# TMS320F280049 register map
Vendor: Texas Instruments; Series: C2000 F28004x; File version: 0.2.0-generated
Registers are 16-bit, read-write, reset 0x0 unless marked. A register's access mark holds for its fields unless they carry their own. Offsets are from the block's base; [hi:lo] are bit positions; {n}, {i} and the like mark numbered series.

## CLA2NOTVISIBLE
Base 0x00002800
0x2C MPISRCSEL2 32-bit — Peripheral Interrupt Source Select Register 2
0x4E MIPCTL — Interrupt Prioriry Register
0x80 MDEBUGCTL — Legacy CLA Debug Control Register
0x82 MDEBUGSS — Legacy CLA Debug Single Step Register
0x84 MPSACTL — CLA PSA Control Register
0x88 MPSA1 32-bit — CLA PSA Register 1
0x8C MPSA2 32-bit — CLA PSA Register 2
0xA0 MHWADBGCAP 32-bit — TI HWA Debug Capabilities
0xA4 MHWADBGCTL 32-bit — TI HWA Debug Control

## ECAP1REGS — ECAP Registers
Base 0x0000A400
Same registers: ECAP2REGS 0x0000A480, ECAP3REGS 0x0000A500, ECAP4REGS 0x0000A580, ECAP5REGS 0x0000A600, ECAP6REGS 0x0000A680, ECAP7REGS 0x0000A700
0x00 TSCTR 32-bit — Time-Stamp Counter
  [31] TSCTR — Time Stamp Counter
0x04 CTRPHS 32-bit — Counter Phase Offset Value Register
  [31] CTRPHS — Counter phase
{0x4+4i} CAP{i} 32-bit (i=1..4) — Capture {i} Register
  [31] CAP{i} — Capture {i}
0x24 ECCTL0 32-bit — Capture Control Register 0
  [12:6] INPUTSEL — INPUT source select
0x28 ECCTL1 — Capture Control Register 1
  [15] FREE_SOFT — Emulation mode
  [15:13] PRESCALE — Event Filter prescale select
  [8] CAPLDEN — Enable Loading CAP1-4 regs on a Cap Event
  [2n-1] CTRRST{n} (n=1..4) — Counter Reset on Capture Event {n}
  [2n-2] CAP{n}POL (n=1..4) — Capture Event {n} Polarity select
0x2A ECCTL2 — Capture Control Register 2
  [15] MODCNTRSTS — modulo counter status
  [14:13] DMAEVTSEL — DMA event select
  [11] CTRFILTRESET — Reset event filter, modulus counter, and interrupt flags.
  [10] APWMPOL — APWM output polarity select
  [9] CAP_APWM — CAP/APWM operating mode select
  [8] SWSYNC — SW forced counter sync
  [8:7] SYNCO_SEL — Sync-out mode
  [5] SYNCI_EN — Counter sync-in select
  [4] TSCTRSTOP — TSCNT counter stop
  [3] REARM — One-shot re-arm
  [3:2] STOP_WRAP — Stop value for one-shot, Wrap for continuous
  [0] CONT_ONESHT — Continuous or one-shot
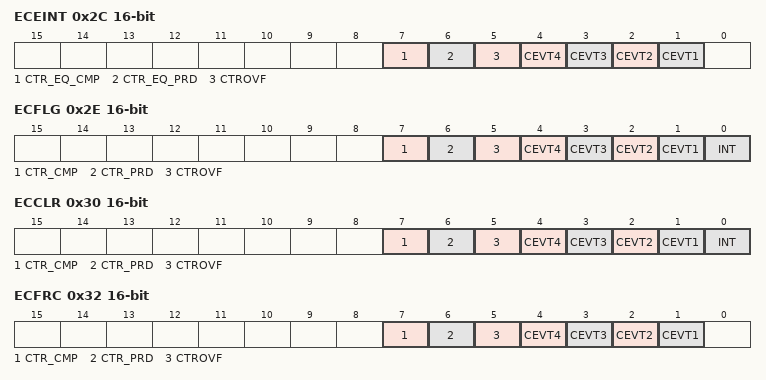
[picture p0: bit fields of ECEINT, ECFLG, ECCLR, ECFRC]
0x2C ECEINT — Capture Interrupt Enable Register
  [7] CTR_EQ_CMP — Compare Equal Interrupt Enable
  [6] CTR_EQ_PRD — Period Equal Interrupt Enable
  [5] CTROVF — Counter Overflow Interrupt Enable
  [n] CEVT{n} (n=1..4) — Capture Event {n} Interrupt Enable
0x2E ECFLG — Capture Interrupt Flag Register
  [7] CTR_CMP — Compare Equal Interrupt Flag
  [6] CTR_PRD — Period Equal Interrupt Flag
  [5] CTROVF — Counter Overflow Interrupt Flag
  [n] CEVT{n} (n=1..4) — Capture Event {n} Interrupt Flag
  [0] INT — Global Flag
0x30 ECCLR — Capture Interrupt Clear Register
  [7] CTR_CMP — Compare Equal Status Clear
  [6] CTR_PRD — Period Equal Status Clear
  [5] CTROVF — Counter Overflow Status Clear
  [n] CEVT{n} (n=1..4) — Capture Event {n} Status Clear
  [0] INT — ECAP Global Interrupt Status Clear
0x32 ECFRC — Capture Interrupt Force Register
  [7] CTR_CMP — Compare Equal Force Interrupt
  [6] CTR_PRD — Period Equal Force Interrupt
  [5] CTROVF — Counter Overflow Force Interrupt
  [n] CEVT{n} (n=1..4) — Capture Event {n} Force Interrupt

## HRCAP6REGS — HRCAP Registers
Base 0x0000A6C0
Same registers: HRCAP7REGS 0x0000A740
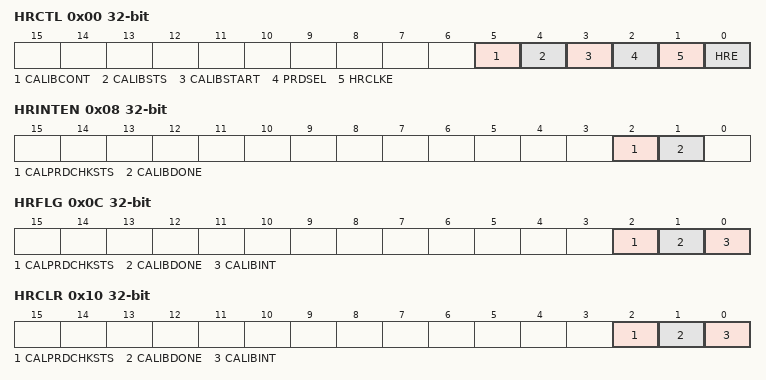
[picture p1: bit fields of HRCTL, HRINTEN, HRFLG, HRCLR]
0x00 HRCTL 32-bit — High-Res Control Register
  [5] CALIBCONT — Continuous mode Calibration Select
  [4] CALIBSTS — Calibration status
  [3] CALIBSTART — Calibration start
  [2] PRDSEL — Calibration Period Match
  [1] HRCLKE — High Resolution Clock Enable
  [0] HRE — High Resolution Enable
0x08 HRINTEN 32-bit — High-Res Calibration Interrupt Enable Register
  [2] CALPRDCHKSTS — Calibration period check status enable
  [1] CALIBDONE — Calibration doe interrupt enable
0x0C HRFLG 32-bit — High-Res Calibration Interrupt Flag Register
  [2] CALPRDCHKSTS — Calibration period check status Flag Bi
  [1] CALIBDONE — Calibration Done Interrupt Flag Bit
  [0] CALIBINT — Global calibration Interrupt Status Flag
0x10 HRCLR 32-bit — High-Res Calibration Interrupt Clear Register
  [2] CALPRDCHKSTS — Clear Calibration period check status Flag Bit
  [1] CALIBDONE — Clear Calibration Done Interrupt Flag Bit
  [0] CALIBINT — Clear Global calibration Interrupt Flag
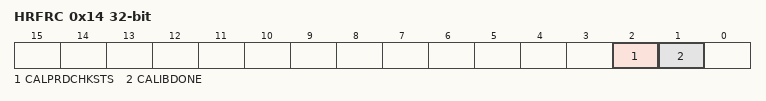
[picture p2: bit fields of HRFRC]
0x14 HRFRC 32-bit — High-Res Calibration Interrupt Force Register
  [2] CALPRDCHKSTS — Force Calibration period check status Flag Bit
  [1] CALIBDONE — Force Calibration Done Interrupt Flag Bit
0x18 HRCALPRD 32-bit — High-Res Calibration Period Register
  [31] PRD — Calibration period
0x1C HRSYSCLKCTR 32-bit — High-Res Calibration SYSCLK Counter Register
  [31] HRSYSCLKCTR — Current SYCLK counter value
0x20 HRSYSCLKCAP 32-bit — High-Res Calibration SYSCLK Capture Register
  [31] HRSYSCLKCAP — Reads captured SYSCLK counter
0x24 HRCLKCTR 32-bit — High-Res Calibration HRCLK Counter Register
  [31] HRCLKCTR — Current HRCLK counter value
0x28 HRCLKCAP 32-bit — High-Res Calibration HRCLK Capture Register
  [31] HRCLKCAP — Reads captured HRCLK counter
